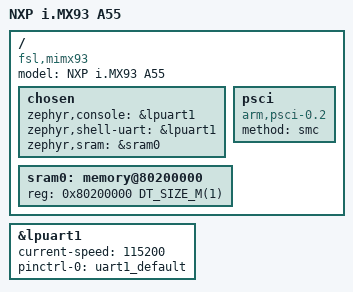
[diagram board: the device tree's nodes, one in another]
/*
 * Copyright 2022 NXP
 *
 * SPDX-License-Identifier: Apache-2.0
 */

/dts-v1/;

#include <nxp/nxp_mimx93_a55.dtsi>
#include "mimx93_evk-pinctrl.dtsi"

/ {
        model = "NXP i.MX93 A55";
        compatible = "fsl,mimx93";

        chosen {
                zephyr,console = &lpuart1;
                zephyr,shell-uart = &lpuart1;
                zephyr,sram = &sram0;
        };

        psci {
                compatible = "arm,psci-0.2";
                method = "smc";
        };

        sram0: memory@80200000 {
                reg = <0x80200000 DT_SIZE_M(1)>;
        };
};

&lpuart1 {
        status = "okay";
        current-speed = <115200>;
        /* clocks = <&ccm IMX_CCM_UART4_CLK 0x6c 24>; */
        pinctrl-0 = <&uart1_default>;
        pinctrl-names = "default";
};

